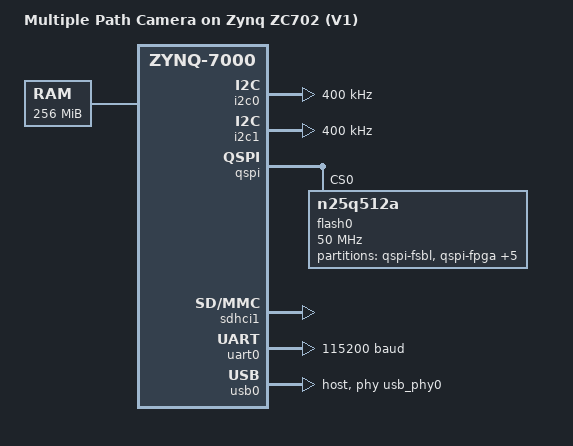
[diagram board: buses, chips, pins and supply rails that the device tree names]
/*
 * CAUTION: This file is automatically generated by Xilinx.
 * Version:  
 * Today is: Thu Jan  3 11:19:25 2019
 */

/dts-v1/;
/include/ "zynq-7000.dtsi"

/ {
	model = "Multiple Path Camera on Zynq ZC702 (V1)";
	compatible = "tdc,mpcam-v1", "xlnx,zynq-zc702", "xlnx,zynq-7000";

	aliases {
		ethernet0 = &gem0;
		i2c0 = &i2c0;
		i2c1 = &i2c1;
		mmc0 = &sdhci1;
		mmc1 = &sdhci0;
		serial0 = &uart0;
		serial1 = &uart1;
		spi0 = &qspi;
	};

	chosen {
		bootargs = "";
		stdout-path = "serial0:115200n8";
	};

	memory {
		device_type = "memory";
		reg = <0x0 0x10000000>;
	};

	usb_phy0: phy0@e0002000 {
		compatible = "ulpi-phy";
		#phy-cells = <0>;
		reg = <0xe0002000 0x1000>;
		view-port = <0x0170>;
		drv-vbus;
	};
};

&clkc {
	fclk-enable = <0x1>;
	ps-clk-frequency = <33333333>;
};

&gem0 {
	status = "disabled";
};

&gpio0 {
	emio-gpio-width = <2>;
	gpio-mask-high = <0x0>;
	gpio-mask-low = <0x5600>;
};

&i2c0 {
	clock-frequency = <400000>;
	status = "okay";
};

&i2c1 {
	clock-frequency = <400000>;
	status = "okay";
};

&intc {
	num_cpus = <2>;
	num_interrupts = <96>;
};

&qspi {
	is-dual = <0>;
	num-cs = <1>;
	status = "okay";

	#address-cells = <1>;
	#size-cells = <0>;

	flash0: flash@0 {
		compatible = "n25q512a","micron,m25p80";
		reg = <0x0>;
		spi-max-frequency = <50000000>;
		#address-cells = <1>;
		#size-cells = <1>;

		partition@00000000 {
			label = "qspi-fsbl";
			reg = <0x00000000 0x00040000>;
		};
		partition@00040000 {
			label = "qspi-fpga";
			reg = <0x00040000 0x00500000>;
		};
		partition@00540000 {
			label = "qspi-u-boot";
			reg = <0x00540000 0x005C0000>;
		};
		partition@005C0000 {
			label = "qspi-u-boot-env";
			reg = <0x005C0000 0x00020000>;
		};
		partition@005E0000 {
			label = "qspi-device-tree";
			reg = <0x005C0000 0x00020000>;
		};
		partition@00600000 {
			label = "qspi-image.itb";
			reg = <0x00600000 0x00A00000>;
		};
		partition@01000000 {
			label = "qspi-rootfs";
			reg = <0x01000000 0x01000000>;
		};
	};
};

/* mmc0: Internal eMMC */
&sdhci1 {
	xlnx,has-cd = <0x0>;
	xlnx,has-power = <0x0>;
	xlnx,has-wp = <0x0>;
	status = "okay";
};

/* mmc1: External SD card */
&sdhci0 {
	xlnx,has-cd = <0x0>;
	xlnx,has-power = <0x0>;
	xlnx,has-wp = <0x0>;
	status = "disabled";
};

&uart0 {
	current-speed = <115200>;
	device_type = "serial";
	port-number = <0>;
	status = "okay";
};

&uart1 {
	current-speed = <115200>;
	device_type = "serial";
	port-number = <1>;
	status = "disabled";
};

&usb0 {
	dr_mode = "host";
	usb-phy = <&usb_phy0>;
	status = "okay";
};

